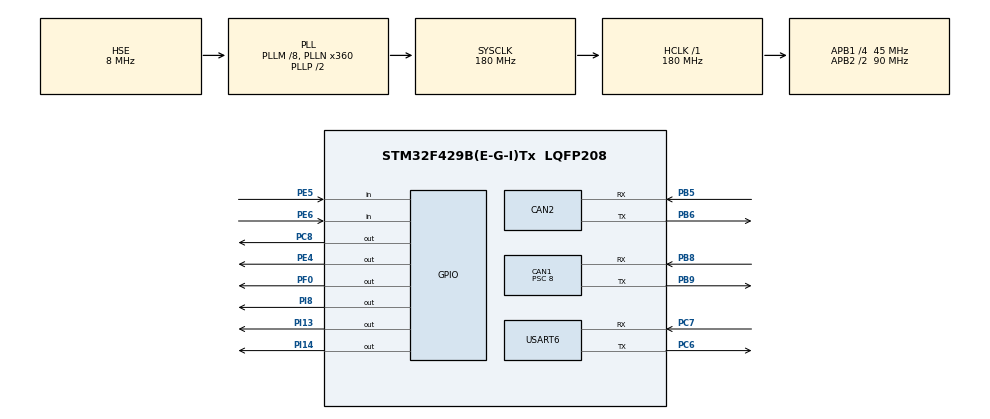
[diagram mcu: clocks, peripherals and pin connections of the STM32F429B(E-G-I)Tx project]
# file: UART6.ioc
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CAN1.ABOM=ENABLE
CAN1.BS1=CAN_BS1_8TQ
CAN1.BS2=CAN_BS2_3TQ
CAN1.CalculateTimeQuantum=177.77777777777777
CAN1.Prescaler=8
CAN2.BS1=CAN_BS1_3TQ
CAN2.BS2=CAN_BS2_5TQ
CAN2.CalculateTimeQuantum=355.55555555555554
Mcu.Family=STM32F4
Mcu.Name=STM32F429B(E-G-I)Tx
Mcu.Package=LQFP208
NVIC.CAN1_RX0_IRQn=true\:0\:0\:false\:false\:true\:true
NVIC.CAN1_TX_IRQn=true\:0\:0\:false\:false\:true\:true
NVIC.PriorityGroup=NVIC_PRIORITYGROUP_4
NVIC.USART6_IRQn=true\:0\:0\:false\:false\:true\:true
PB5.Mode=Slave
PB5.Signal=CAN2_RX
PB6.Mode=Slave
PB6.Signal=CAN2_TX
PB8.Mode=Master
PB8.Signal=CAN1_RX
PB9.Mode=Master
PB9.Signal=CAN1_TX
PC14/OSC32_IN.Mode=LSE-External-Oscillator
PC14/OSC32_IN.Signal=RCC_OSC32_IN
PC15/OSC32_OUT.Mode=LSE-External-Oscillator
PC15/OSC32_OUT.Signal=RCC_OSC32_OUT
PC6.Mode=Asynchronous
PC6.Signal=USART6_TX
PC7.Mode=Asynchronous
PC7.Signal=USART6_RX
PC8.Signal=GPIO_Output
PE4.GPIO_ModeDefaultOutputPP=GPIO_MODE_OUTPUT_PP
PE4.GPIO_PuPd=GPIO_NOPULL
PE4.GPIO_Speed=GPIO_SPEED_FREQ_LOW
PE4.PinState=GPIO_PIN_RESET
PE4.Signal=GPIO_Output
PE5.GPIO_Mode=GPIO_MODE_INPUT
PE5.GPIO_PuPd=GPIO_NOPULL
PE5.Signal=GPIO_Input
PE6.GPIO_Mode=GPIO_MODE_INPUT
PE6.GPIO_PuPd=GPIO_NOPULL
PE6.Signal=GPIO_Input
PF0.Signal=GPIO_Output
PH0/OSC_IN.Mode=HSE-External-Oscillator
PH0/OSC_IN.Signal=RCC_OSC_IN
PH1/OSC_OUT.Mode=HSE-External-Oscillator
PH1/OSC_OUT.Signal=RCC_OSC_OUT
PI13.Signal=GPIO_Output
PI14.Signal=GPIO_Output
PI8.GPIO_ModeDefaultOutputPP=GPIO_MODE_OUTPUT_PP
PI8.GPIO_PuPd=GPIO_NOPULL
PI8.GPIO_Speed=GPIO_SPEED_FREQ_LOW
PI8.PinState=GPIO_PIN_RESET
PI8.Signal=GPIO_Output
ProjectManager.HeapSize=0x200
ProjectManager.StackSize=0x400
ProjectManager.TargetToolchain=MDK-ARM V5
RCC.48MHZClocksFreq_Value=90000000
RCC.AHBFreq_Value=180000000
RCC.APB1CLKDivider=RCC_HCLK_DIV4
RCC.APB1Freq_Value=45000000
RCC.APB1TimFreq_Value=90000000
RCC.APB2CLKDivider=RCC_HCLK_DIV2
RCC.APB2Freq_Value=90000000
RCC.APB2TimFreq_Value=180000000
RCC.CortexFreq_Value=180000000
RCC.HCLKFreq_Value=180000000
RCC.HSE_VALUE=8000000
RCC.HSI_VALUE=16000000
RCC.PLLM=8
RCC.PLLN=360
RCC.PLLSourceVirtual=RCC_PLLSOURCE_HSE
RCC.RCC_RTC_Clock_Source=RCC_RTCCLKSOURCE_LSE
RCC.RCC_RTC_Clock_SourceVirtual=RCC_RTCCLKSOURCE_LSE
RCC.SYSCLKFreq_VALUE=180000000
RCC.SYSCLKSource=RCC_SYSCLKSOURCE_PLLCLK
RCC.VCOOutputFreq_Value=360000000
USART6.Parity=PARITY_EVEN
USART6.VirtualMode=VM_ASYNC
USART6.WordLength=WORDLENGTH_9B
VP_RTC_VS_RTC_Activate.Mode=RTC_Enabled
board=UART6

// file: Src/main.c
/* USER CODE BEGIN Header */
/**
  ******************************************************************************
  * @file           : main.c
  * @brief          : Main program body
  ******************************************************************************
  ** This notice applies to any and all portions of this file
  * that are not between comment pairs USER CODE BEGIN and
  * USER CODE END. Other portions of this file, whether
  * inserted by the user or by software development tools
  * are owned by their respective copyright owners.
  *
  * COPYRIGHT(c) 2019 STMicroelectronics
  *
  * Redistribution and use in source and binary forms, with or without modification,
  * are permitted provided that the following conditions are met:
  *   1. Redistributions of source code must retain the above copyright notice,
  *      this list of conditions and the following disclaimer.
  *   2. Redistributions in binary form must reproduce the above copyright notice,
  *      this list of conditions and the following disclaimer in the documentation
  *      and/or other materials provided with the distribution.
  *   3. Neither the name of STMicroelectronics nor the names of its contributors
  *      may be used to endorse or promote products derived from this software
  *      without specific prior written permission.
  *
  * THIS SOFTWARE IS PROVIDED BY THE COPYRIGHT HOLDERS AND CONTRIBUTORS "AS IS"
  * AND ANY EXPRESS OR IMPLIED WARRANTIES, INCLUDING, BUT NOT LIMITED TO, THE
  * IMPLIED WARRANTIES OF MERCHANTABILITY AND FITNESS FOR A PARTICULAR PURPOSE ARE
  * DISCLAIMED. IN NO EVENT SHALL THE COPYRIGHT HOLDER OR CONTRIBUTORS BE LIABLE
  * FOR ANY DIRECT, INDIRECT, INCIDENTAL, SPECIAL, EXEMPLARY, OR CONSEQUENTIAL
  * DAMAGES (INCLUDING, BUT NOT LIMITED TO, PROCUREMENT OF SUBSTITUTE GOODS OR
  * SERVICES; LOSS OF USE, DATA, OR PROFITS; OR BUSINESS INTERRUPTION) HOWEVER
  * CAUSED AND ON ANY THEORY OF LIABILITY, WHETHER IN CONTRACT, STRICT LIABILITY,
  * OR TORT (INCLUDING NEGLIGENCE OR OTHERWISE) ARISING IN ANY WAY OUT OF THE USE
  * OF THIS SOFTWARE, EVEN IF ADVISED OF THE POSSIBILITY OF SUCH DAMAGE.
  *
  ******************************************************************************
  */
/* USER CODE END Header */

#include "main.h"

/* USER CODE BEGIN Includes */
#include "stm32f4xx_hal.h"
/* USER CODE END Includes */

CAN_HandleTypeDef hcan1;
CAN_HandleTypeDef hcan2;

RTC_HandleTypeDef hrtc;

UART_HandleTypeDef huart6;

/* USER CODE BEGIN PV */
/* Private variables ---------------------------------------------------------*/
//! Makro for the delay times

/* Private variables ---------------------------------------------------------*/
uint8_t aTxStartMessage[] = "\r\n****UART-Hyperterminal communication based on IT ****\r\nEnter 10 characters using keyboard :\r\n";

/* Buffer used for reception */
uint8_t aRxBuffer[20];
/* USER CODE END PV */

void SystemClock_Config(void);
static void MX_GPIO_Init(void);
static void MX_USART6_UART_Init(void);
static void MX_RTC_Init(void);
static void MX_CAN1_Init(void);
static void MX_CAN2_Init(void);
/* USER CODE BEGIN PFP */
/* Private function prototypes -----------------------------------------------*/

/* USER CODE END PFP */

int main(void)
{

  /* MCU Configuration--------------------------------------------------------*/

  /* Reset of all peripherals, Initializes the Flash interface and the Systick. */
  HAL_Init();

  /* Configure the system clock */
  SystemClock_Config();

  /* Initialize all configured peripherals */
  MX_GPIO_Init();
  MX_USART6_UART_Init();
  MX_RTC_Init();
  MX_CAN1_Init();
  MX_CAN2_Init();
  /* USER CODE BEGIN 2 */

	HAL_UART_Transmit_IT(&huart6, (uint8_t *)aTxStartMessage, sizeof(aTxStartMessage));
  HAL_UART_Receive_IT(&huart6, (uint8_t *)aRxBuffer, 10);

  /* USER CODE END 2 */

  /* Infinite loop */
  /* USER CODE BEGIN WHILE */
  while (1)
  {

	HAL_GPIO_WritePin(GPIOC,GPIO_PIN_8,GPIO_PIN_SET);
	if(HAL_GPIO_ReadPin(GPIOC,GPIO_PIN_8)){
		HAL_UART_Transmit_IT(&huart6, (uint8_t *)aTxStartMessage, sizeof(aTxStartMessage));
	}
	HAL_GPIO_WritePin(GPIOC,GPIO_PIN_8,GPIO_PIN_RESET);

    /* USER CODE END WHILE */

  }
}

void SystemClock_Config(void)
{
  RCC_OscInitTypeDef RCC_OscInitStruct = {0};
  RCC_ClkInitTypeDef RCC_ClkInitStruct = {0};
  RCC_PeriphCLKInitTypeDef PeriphClkInitStruct = {0};

  /**Configure the main internal regulator output voltage
  */
  __HAL_RCC_PWR_CLK_ENABLE();
  __HAL_PWR_VOLTAGESCALING_CONFIG(PWR_REGULATOR_VOLTAGE_SCALE1);
  /**Initializes the CPU, AHB and APB busses clocks
  */
  RCC_OscInitStruct.OscillatorType = RCC_OSCILLATORTYPE_HSE|RCC_OSCILLATORTYPE_LSE;
  RCC_OscInitStruct.HSEState = RCC_HSE_ON;
  RCC_OscInitStruct.LSEState = RCC_LSE_ON;
  RCC_OscInitStruct.PLL.PLLState = RCC_PLL_ON;
  RCC_OscInitStruct.PLL.PLLSource = RCC_PLLSOURCE_HSE;
  RCC_OscInitStruct.PLL.PLLM = 8;
  RCC_OscInitStruct.PLL.PLLN = 360;
  RCC_OscInitStruct.PLL.PLLP = RCC_PLLP_DIV2;
  RCC_OscInitStruct.PLL.PLLQ = 4;
  if (HAL_RCC_OscConfig(&RCC_OscInitStruct) != HAL_OK)
  {
    Error_Handler();
  }
  /**Activate the Over-Drive mode
  */
  if (HAL_PWREx_EnableOverDrive() != HAL_OK)
  {
    Error_Handler();
  }
  /**Initializes the CPU, AHB and APB busses clocks
  */
  RCC_ClkInitStruct.ClockType = RCC_CLOCKTYPE_HCLK|RCC_CLOCKTYPE_SYSCLK
                              |RCC_CLOCKTYPE_PCLK1|RCC_CLOCKTYPE_PCLK2;
  RCC_ClkInitStruct.SYSCLKSource = RCC_SYSCLKSOURCE_PLLCLK;
  RCC_ClkInitStruct.AHBCLKDivider = RCC_SYSCLK_DIV1;
  RCC_ClkInitStruct.APB1CLKDivider = RCC_HCLK_DIV4;
  RCC_ClkInitStruct.APB2CLKDivider = RCC_HCLK_DIV2;

  if (HAL_RCC_ClockConfig(&RCC_ClkInitStruct, FLASH_LATENCY_5) != HAL_OK)
  {
    Error_Handler();
  }
  PeriphClkInitStruct.PeriphClockSelection = RCC_PERIPHCLK_RTC;
  PeriphClkInitStruct.RTCClockSelection = RCC_RTCCLKSOURCE_LSE;
  if (HAL_RCCEx_PeriphCLKConfig(&PeriphClkInitStruct) != HAL_OK)
  {
    Error_Handler();
  }
}

static void MX_CAN1_Init(void)
{

  hcan1.Instance = CAN1;
  hcan1.Init.Prescaler = 8;
  hcan1.Init.Mode = CAN_MODE_NORMAL;
  hcan1.Init.SyncJumpWidth = CAN_SJW_1TQ;
  hcan1.Init.TimeSeg1 = CAN_BS1_8TQ;
  hcan1.Init.TimeSeg2 = CAN_BS2_3TQ;
  hcan1.Init.TimeTriggeredMode = DISABLE;
  hcan1.Init.AutoBusOff = ENABLE;
  hcan1.Init.AutoWakeUp = DISABLE;
  hcan1.Init.AutoRetransmission = DISABLE;
  hcan1.Init.ReceiveFifoLocked = DISABLE;
  hcan1.Init.TransmitFifoPriority = DISABLE;
  if (HAL_CAN_Init(&hcan1) != HAL_OK)
  {
    Error_Handler();
  }

}

static void MX_CAN2_Init(void)
{

  hcan2.Instance = CAN2;
  hcan2.Init.Prescaler = 16;
  hcan2.Init.Mode = CAN_MODE_NORMAL;
  hcan2.Init.SyncJumpWidth = CAN_SJW_1TQ;
  hcan2.Init.TimeSeg1 = CAN_BS1_3TQ;
  hcan2.Init.TimeSeg2 = CAN_BS2_5TQ;
  hcan2.Init.TimeTriggeredMode = DISABLE;
  hcan2.Init.AutoBusOff = DISABLE;
  hcan2.Init.AutoWakeUp = DISABLE;
  hcan2.Init.AutoRetransmission = DISABLE;
  hcan2.Init.ReceiveFifoLocked = DISABLE;
  hcan2.Init.TransmitFifoPriority = DISABLE;
  if (HAL_CAN_Init(&hcan2) != HAL_OK)
  {
    Error_Handler();
  }

}

static void MX_RTC_Init(void)
{

  /**Initialize RTC Only
  */
  hrtc.Instance = RTC;
  hrtc.Init.HourFormat = RTC_HOURFORMAT_24;
  hrtc.Init.AsynchPrediv = 127;
  hrtc.Init.SynchPrediv = 255;
  hrtc.Init.OutPut = RTC_OUTPUT_DISABLE;
  hrtc.Init.OutPutPolarity = RTC_OUTPUT_POLARITY_HIGH;
  hrtc.Init.OutPutType = RTC_OUTPUT_TYPE_OPENDRAIN;
  if (HAL_RTC_Init(&hrtc) != HAL_OK)
  {
    Error_Handler();
  }

}

static void MX_USART6_UART_Init(void)
{

  huart6.Instance = USART6;
  huart6.Init.BaudRate = 115200;
  huart6.Init.WordLength = UART_WORDLENGTH_9B;
  huart6.Init.StopBits = UART_STOPBITS_1;
  huart6.Init.Parity = UART_PARITY_EVEN;
  huart6.Init.Mode = UART_MODE_TX_RX;
  huart6.Init.HwFlowCtl = UART_HWCONTROL_NONE;
  huart6.Init.OverSampling = UART_OVERSAMPLING_16;
  if (HAL_UART_Init(&huart6) != HAL_OK)
  {
    Error_Handler();
  }

}

static void MX_GPIO_Init(void)
{
  GPIO_InitTypeDef GPIO_InitStruct = {0};

  /* GPIO Ports Clock Enable */
  __HAL_RCC_GPIOE_CLK_ENABLE();
  __HAL_RCC_GPIOI_CLK_ENABLE();
  __HAL_RCC_GPIOC_CLK_ENABLE();
  __HAL_RCC_GPIOF_CLK_ENABLE();
  __HAL_RCC_GPIOH_CLK_ENABLE();
  __HAL_RCC_GPIOB_CLK_ENABLE();

  /*Configure GPIO pin Output Level */
  HAL_GPIO_WritePin(GPIOE, GPIO_PIN_4, GPIO_PIN_RESET);

  /*Configure GPIO pin Output Level */
  HAL_GPIO_WritePin(GPIOI, GPIO_PIN_8|GPIO_PIN_13|GPIO_PIN_14, GPIO_PIN_RESET);

  /*Configure GPIO pin Output Level */
  HAL_GPIO_WritePin(GPIOF, GPIO_PIN_0, GPIO_PIN_RESET);

  /*Configure GPIO pin Output Level */
  HAL_GPIO_WritePin(GPIOC, GPIO_PIN_8, GPIO_PIN_RESET);

  /*Configure GPIO pin : PE4 */
  GPIO_InitStruct.Pin = GPIO_PIN_4;
  GPIO_InitStruct.Mode = GPIO_MODE_OUTPUT_PP;
  GPIO_InitStruct.Pull = GPIO_NOPULL;
  GPIO_InitStruct.Speed = GPIO_SPEED_FREQ_LOW;
  HAL_GPIO_Init(GPIOE, &GPIO_InitStruct);

  /*Configure GPIO pins : PE5 PE6 */
  GPIO_InitStruct.Pin = GPIO_PIN_5|GPIO_PIN_6;
  GPIO_InitStruct.Mode = GPIO_MODE_INPUT;
  GPIO_InitStruct.Pull = GPIO_NOPULL;
  HAL_GPIO_Init(GPIOE, &GPIO_InitStruct);

  /*Configure GPIO pins : PI8 PI13 PI14 */
  GPIO_InitStruct.Pin = GPIO_PIN_8|GPIO_PIN_13|GPIO_PIN_14;
  GPIO_InitStruct.Mode = GPIO_MODE_OUTPUT_PP;
  GPIO_InitStruct.Pull = GPIO_NOPULL;
  GPIO_InitStruct.Speed = GPIO_SPEED_FREQ_LOW;
  HAL_GPIO_Init(GPIOI, &GPIO_InitStruct);

  /*Configure GPIO pin : PF0 */
  GPIO_InitStruct.Pin = GPIO_PIN_0;
  GPIO_InitStruct.Mode = GPIO_MODE_OUTPUT_PP;
  GPIO_InitStruct.Pull = GPIO_NOPULL;
  GPIO_InitStruct.Speed = GPIO_SPEED_FREQ_LOW;
  HAL_GPIO_Init(GPIOF, &GPIO_InitStruct);

  /*Configure GPIO pin : PC8 */
  GPIO_InitStruct.Pin = GPIO_PIN_8;
  GPIO_InitStruct.Mode = GPIO_MODE_OUTPUT_PP;
  GPIO_InitStruct.Pull = GPIO_NOPULL;
  GPIO_InitStruct.Speed = GPIO_SPEED_FREQ_LOW;
  HAL_GPIO_Init(GPIOC, &GPIO_InitStruct);

}

/* USER CODE BEGIN 4 */
	/**
  * @brief Rx Transfer completed callbacks
  * @param huart: uart handle
  * @retval None
  */
void HAL_UART_RxCpltCallback(UART_HandleTypeDef *huart)
{
  /* Prevent unused argument(s) compilation warning */
  UNUSED(huart);

  /* NOTE : This function should not be modified, when the callback is needed,
            the HAL_UART_RxCpltCallback can be implemented in the user file
   */
    HAL_UART_Transmit(&huart6, (uint8_t *)aRxBuffer, 10,0xFFFF);
}
/* USER CODE END 4 */

void Error_Handler(void)
{
  while(1)
  {
  }
}

/************************ (C) COPYRIGHT STMicroelectronics *****END OF FILE****/
